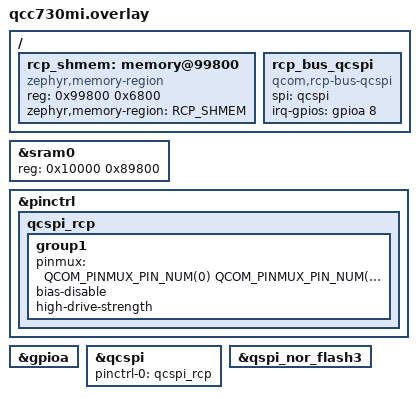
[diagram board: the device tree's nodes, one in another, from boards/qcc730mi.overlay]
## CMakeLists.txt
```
# Copyright (c) Qualcomm Technologies, Inc. and/or its subsidiaries.
# SPDX-License-Identifier: BSD-3-Clause-Clear
#
# qapp/rcp_app: QCC730 board port of the upstream rcp_zephyr sample app.
# Proxy source files (proxy_wifi_mgmt.c, proxy_wifi_data.c) are referenced
# directly from qrcp/rcp_zephyr/samples/rcp_app/src/ to avoid duplication.

cmake_minimum_required(VERSION 3.20.0)

set(UPSTREAM_RCP_APP
    ${CMAKE_CURRENT_LIST_DIR}/../../qrcp/rcp_zephyr/samples/rcp_app/src)

list(APPEND EXTRA_ZEPHYR_MODULES
    ${CMAKE_CURRENT_LIST_DIR}/../../qrcp/rcp_zephyr
    ${CMAKE_CURRENT_LIST_DIR}/../../qrcp/rcp_protocol
    ${CMAKE_CURRENT_LIST_DIR}/../../modules/lib/nanopb
)

find_package(Zephyr REQUIRED HINTS $ENV{ZEPHYR_BASE})
project(rcp_app)

target_sources(app PRIVATE
    src/main.c
    ${UPSTREAM_RCP_APP}/proxy_wifi_data.c
    ${UPSTREAM_RCP_APP}/proxy_wifi_mgmt.c
)

# Proxy headers live in the upstream src dir
target_include_directories(app PRIVATE ${UPSTREAM_RCP_APP})

# Nanopb: generate wifi_mgmt.pb.h/.c from the protocol proto
list(APPEND CMAKE_MODULE_PATH ${ZEPHYR_BASE}/modules/nanopb)
include(nanopb)
zephyr_nanopb_sources(app ${ZEPHYR_RCP_PROTOCOL_MODULE_DIR}/proto/wifi_mgmt.proto)

# Linker fragment: place .rcp_shmem in the RCP_SHMEM memory region
zephyr_linker_sources(SECTIONS src/rcp_shmem.ld)
```

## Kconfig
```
# Copyright (c) Qualcomm Technologies, Inc. and/or its subsidiaries.
# SPDX-License-Identifier: BSD-3-Clause-Clear

mainmenu "QCC730 RCP application"

# Generate CONFIG_QUALCOMM_RCP_APP_LOG_LEVEL (used by upstream proxy sources)
module = QUALCOMM_RCP_APP
module-str = qualcomm_rcp_app
source "subsys/logging/Kconfig.template.log_config"

config USE_DUMMY_WIFI_MGMT_DATA
	bool "Use dummy WiFi management data for unsupported requests"
	default n

config INCLUDE_TRANSPORT_TESTS
	bool "Include RCP transport tests for validation"
	default n

config QUALCOMM_RCP_INIT_PRIORITY
	int "Init priority of RCP initialization"
	default 80

source "Kconfig.zephyr"
```

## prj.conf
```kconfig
# Copyright (c) Qualcomm Technologies, Inc. and/or its subsidiaries.
# SPDX-License-Identifier: BSD-3-Clause-Clear
#
# QCC730 RCP app: QCC730-specific config layer on top of the upstream
# rcp_zephyr sample app. Values here either override or supplement the
# upstream prj.conf defaults.

# RCP bus (QCC730-specific)
CONFIG_QUALCOMM_RCP_BUS_DRIVERS=y
CONFIG_QCC730_RCP_BUS_QCSPI=y
CONFIG_QUALCOMM_RCP_DEFAULT_BUS_SPI=y
CONFIG_GPIO=y
# QcSPI hardware driver — required for HOST_INT0/1 ISR (ring_rx/tx handlers)
CONFIG_SPI=y
CONFIG_SPI_QCC730=y

# RCP protocol (aligned with upstream tuning)
CONFIG_QUALCOMM_RCP_PROTOCOL_NUM_BUFFERS=40
CONFIG_QUALCOMM_RCP_RCP_MAX_TX_EVENTS=40
CONFIG_QUALCOMM_RCP_SEQ_NUM_ACK_WINDOW=7
CONFIG_QUALCOMM_RCP_PROTOCOL_BUFFER_SIZE=1600
CONFIG_QUALCOMM_RCP_INIT_PRIORITY=80

# Init: loopback test stream
CONFIG_INCLUDE_TRANSPORT_TESTS=y

# WiFi
CONFIG_QWIFI=y
CONFIG_WIFI=y
CONFIG_WIFI_QCOM=y
CONFIG_NET_L2_ETHERNET=y
CONFIG_ETH_DRIVER=y
CONFIG_ETH_PHY_DRIVER=y
CONFIG_WIFI_NM=y
CONFIG_WIFI_NM_MAX_MANAGED_INTERFACES=2

# Networking
CONFIG_NETWORKING=y
CONFIG_NET_IPV4=y
CONFIG_NET_DHCPV4=y
CONFIG_NET_DHCPV4_SERVER=y
# In RCP mode QCC730 is a transparent L2 proxy — the host (RPi) runs DHCP.
# Disabling auto-DHCP prevents QCC730 from claiming its own IP, which would
# cause the AP to see two clients and may cause DHCP Offers to be consumed
# by QCC730's own network stack before reaching the host.
CONFIG_WIFI_QCOM_AUTO_DHCPV4=n
CONFIG_NET_DHCPV4_INITIAL_DELAY_MAX=2
CONFIG_NET_SOCKETS=y
CONFIG_NET_SOCKETS_PACKET=y
CONFIG_NET_MGMT=y
CONFIG_NET_MGMT_EVENT=y
CONFIG_NET_MGMT_EVENT_QUEUE_SIZE=8
CONFIG_NET_MGMT_EVENT_STACK_SIZE=2560
CONFIG_NET_CONTEXT_RCVTIMEO=y

# Network buffers (upstream tuning)
CONFIG_NET_CONTEXT_NET_PKT_POOL=y
CONFIG_NET_PKT_RX_COUNT=16
CONFIG_NET_PKT_TX_COUNT=16
CONFIG_NET_BUF_RX_COUNT=16
CONFIG_NET_BUF_TX_COUNT=16
CONFIG_NET_BUF_DATA_SIZE=1514

# Kernel
CONFIG_MAIN_STACK_SIZE=4096
CONFIG_SYSTEM_WORKQUEUE_STACK_SIZE=1024
CONFIG_HEAP_MEM_POOL_SIZE=131072
CONFIG_DYNAMIC_THREAD=y
CONFIG_DYNAMIC_THREAD_ALLOC=y
CONFIG_DYNAMIC_THREAD_PREFER_POOL=y

# Nanopb (needed by proxy_wifi_mgmt.c)
CONFIG_NANOPB=y

# Entropy (required by networking stack for random port/seq numbers)
CONFIG_TEST_RANDOM_GENERATOR=y

# Logging
CONFIG_LOG=y
CONFIG_LOG_MODE_MINIMAL=y
CONFIG_PRINTK=y

# Shell (serial debug)
CONFIG_SHELL=y
CONFIG_SHELL_BACKENDS=y
CONFIG_SHELL_BACKEND_SERIAL=y
CONFIG_SHELL_STACK_SIZE=4096
CONFIG_NET_SHELL=y
CONFIG_NET_L2_WIFI_SHELL=y

# Disable features not used in RCP mode
CONFIG_RING_SERVICE=n
CONFIG_BT=n

# Power management — required for BMPS + S2RAM low power (RCP lowpower feature)
CONFIG_PM=y
CONFIG_PM_DEVICE=y

CONFIG_QCRYPTO=y
CONFIG_MBEDTLS=y
CONFIG_MBEDTLS_TEST=y

# counter driver.
CONFIG_COUNTER=y
```

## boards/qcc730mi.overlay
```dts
/*
 * Copyright (c) Qualcomm Technologies, Inc. and/or its subsidiaries.
 *
 * SPDX-License-Identifier: BSD-3-Clause-Clear
 */

#include <zephyr/dt-bindings/pinctrl/qcom-qcc730-pinctrl.h>

/ {
	rcp_shmem: memory@99800 {
		compatible = "zephyr,memory-region", "mmio-sram";
		reg = <0x99800 0x6800>;
		zephyr,memory-region = "RCP_SHMEM";
	};

	rcp_bus_qcspi: rcp_bus_qcspi {
		compatible = "qcom,rcp-bus-qcspi";
		spi = <&qcspi>;
		irq-gpios = <&gpioa 8 GPIO_ACTIVE_HIGH>;
	};
};

/* Shrink sram0 to leave room for .rcp_shmem at top */
&sram0 {
	reg = <0x10000 0x89800>;
};

&pinctrl {
	qcspi_rcp: qcspi_rcp {
		group1 {
			pinmux = <
				QCOM_PINMUX_PIN_NUM(0)  /* CLK  - GPIO0 */
				QCOM_PINMUX_PIN_NUM(3)  /* MISO - GPIO3 */
				QCOM_PINMUX_PIN_NUM(2)  /* MOSI - GPIO2 */
			>;
			bias-disable;
			high-drive-strength;
		};
	};
};

&gpioa {
	status = "okay";
};

&qcspi {
	status = "okay";
	pinctrl-0 = <&qcspi_rcp>;
	pinctrl-names = "default";
};

&qspi_nor_flash3 {
	status = "okay";
};
```

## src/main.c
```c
/*
 * Copyright (c) Qualcomm Technologies, Inc. and/or its subsidiaries.
 *
 * SPDX-License-Identifier: BSD-3-Clause-Clear
 */

#include <zephyr/logging/log.h>
#include <zephyr/kernel.h>

#include <rcp_interface_impl.h>
#include <rcp_cntrl_msgs.h>
#include <rcp_config.h>

#include "proxy_wifi_data.h"
#include "proxy_wifi_mgmt.h"

LOG_MODULE_REGISTER(rcp_app, CONFIG_QUALCOMM_RCP_APP_LOG_LEVEL);

#define RCP_INIT_PRIORITY    CONFIG_QUALCOMM_RCP_INIT_PRIORITY
#define EVT_LOOP_STACK_SIZE  2048
#define EVT_LOOP_PRIORITY    8

static int sys_init_rcp(void)
{
	(void)init_rcp();
	return 0;
}

SYS_INIT(sys_init_rcp, POST_KERNEL, RCP_INIT_PRIORITY);

static void event_loop_thread(void *p1, void *p2, void *p3)
{
	ARG_UNUSED(p1);
	ARG_UNUSED(p2);
	ARG_UNUSED(p3);
	run_event_loop();

}

K_THREAD_DEFINE(event_loop_tid, EVT_LOOP_STACK_SIZE,
		event_loop_thread, NULL, NULL, NULL,
		EVT_LOOP_PRIORITY, 0, 0);

int main(void)
{
	uint8_t capabilities = 0;

	if (!proxy_wifi_mgmt_init()) {
		LOG_ERR("Failed to initialize Wi-Fi mgmt proxy");
		return 0;
	}
	if (!proxy_wifi_data_init()) {
		LOG_ERR("Failed to initialize Wi-Fi data proxy");
		return 0;
	}
	capabilities |= RCP_WIFI_CAPABILITY_FLAG;

	init_mcu_capability(capabilities);
	return 0;
}
```
